# R7FA2A1AB register map
Vendor: Renesas; Series: RA2; File version: 1.1
CPU: CM23 r1p0, little endian, MPU, no FPU, VTOR, 2 interrupt priority bits
Registers are 8-bit, read-write, reset 0x0 unless marked. A register's access mark holds for its fields unless they carry their own. Offsets are from the block's base; [hi:lo] are bit positions; {n}, {i} and the like mark numbered series.

## SDADC24 — 24-Bit Sigma,Delta A/D Converter
Base 0x4009C000
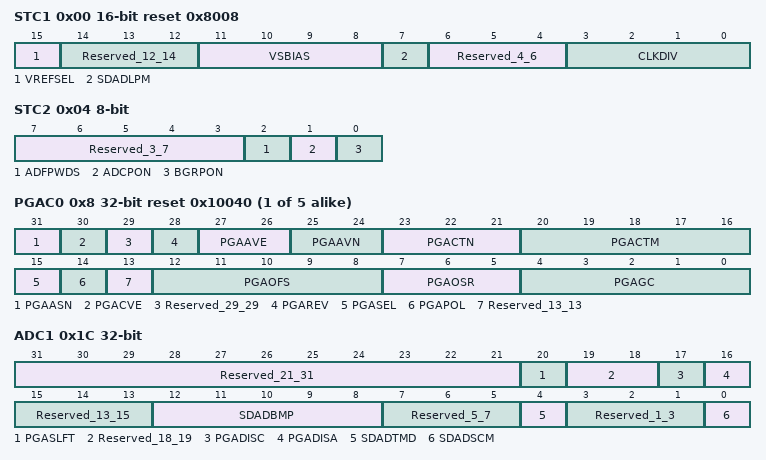
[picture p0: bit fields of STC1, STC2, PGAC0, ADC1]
0x00 STC1 16-bit reset 0x8008 — Startup Control Register 1
  [15] VREFSEL — VREF mode select
  [14:12] Reserved_12_14 — These bits are read as 000. The write value should be 000.
  [11:8] VSBIAS — Reference voltage select
  [7] SDADLPM — A/D conversion operation mode select
  [6:4] Reserved_4_6 — These bits are read as 000. The write value should be 000.
  [3:0] CLKDIV — SDADC24 reference clock division select
0x04 STC2 — Startup Control Register 2
  [7:3] Reserved_3_7 — These bits are read as 00000. The write value should be 00000.
  [2] ADFPWDS — ADREG forced power,down mode
  [1] ADCPON — ADC reference supply part power control
  [0] BGRPON — BGR part power control
{0x8+4i} PGAC{i} (i=0..4) 32-bit reset 0x10040 — Input Multiplexer {i} Setting Register
  [31] PGAASN — Selection of the mode for specifying the number of A/D conversions in ADSCAN
  [30] PGACVE — Calibration enable
  [29] Reserved_29_29 — This bit is read as 0. The write value should be 0.
  [28] PGAREV — Single,End Input A/D Converted Data Inversion Select
  [27:26] PGAAVE — Selection of averaging processing
  [25:24] PGAAVN — Selection of the number of data to be averaged
  [23:21] PGACTN — Coefficient (n) selection of the A/D conversion count (N) in AUTOSCAN
  [20:16] PGACTM — Coefficient (m) selection of the A/D conversion count (N) in AUTOSCAN
  [15] PGASEL — Analog Channel Input Mode Select
  [14] PGAPOL — Polarity select
  [13] Reserved_13_13 — This bit is read as 0. The write value should be 0.
  [12:8] PGAOFS — Offset voltage select
  [7:5] PGAOSR — Oversampling ratio select
  [4:0] PGAGC — Gain selection of a programmable gain instrumentation amplifier ( Gset1, Gset2, Gtotal )
0x1C ADC1 32-bit — Sigma,delta A/D Converter Control Register 1
  [31:21] Reserved_21_31 — These bits are read as 00000000000. The write value should be 00000000000.
  [20] PGASLFT — PGA offset self,diagnosis enable
  [19:18] Reserved_18_19 — These bits are read as 00. The write value should be 00.
  [17] PGADISC — Disconnection Detection Assist Setting
  [16] PGADISA — Control of disconnection detection
  [15:13] Reserved_13_15 — These bits are read as 000. The write value should be 000.
  [12:8] SDADBMP — A/D conversion control of the signal from input multiplexer
  [7:5] Reserved_5_7 — These bits are read as 000. The write value should be 000.
  [4] SDADTMD — Selection of A/D conversion trigger signal
  [3:1] Reserved_1_3 — These bits are read as 000. The write value should be 000.
  [0] SDADSCM — Selection of autoscan mode
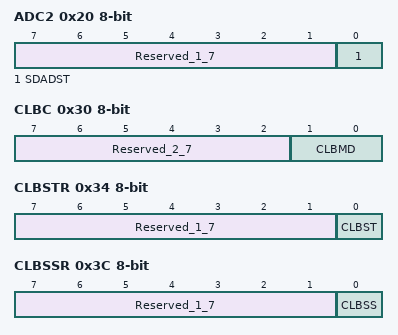
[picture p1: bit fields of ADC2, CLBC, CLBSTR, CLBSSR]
0x20 ADC2 — Sigma,delta A/D Converter Control Register 2
  [7:1] Reserved_1_7 — These bits are read as 0000000. The write value should be 0000000.
  [0] SDADST — Control of A/D conversion
0x24 ADCR 32-bit — Sigma,delta A/D Converter Conversion Result Register
  [31:28] Reserved_28_31 — These bits are read as 0000. The write value should be 0000.
  [27:25] SDADCRC ro — Channel number for an A/D conversion result
  [24] SDADCRS ro — Status of an A/D conversion result
  [23:0] SDADCRD ro — The 24-bit A/D conversion result
  [15:0] Reserved_0_15 — These bits are read as 0000000000000000. The write value should be 0000000000000000.
0x28 ADAR 32-bit ro — Sigma,delta A/D Converter Average Value Register
  [31:28] Reserved_28_31 — These bits are read as 0000.
  [27:25] SDADMVC — Channel number for an A/D conversion result
  [24] SDADMVS — Status of an A/D conversion result
  [23:0] SDADMVD — The 24-bit A/D average value
  [15:0] Reserved_0_15 — These bits are read as 0000000000000000.
0x30 CLBC — Calibration Control Register
  [7:2] Reserved_2_7 — These bits are read as 000000. The write value should be 000000.
  [1:0] CLBMD — These bits are read as 0. The write value should be 0.
0x34 CLBSTR — Calibration Start Control Register
  [7:1] Reserved_1_7 — These bits are read as 0000000. The write value should be 0000000.
  [0] CLBST — Calibration start control
0x3C CLBSSR ro — Calibration Status Register
  [7:1] Reserved_1_7 — These bits are read as 0000000.
  [0] CLBSS — Calibration status
